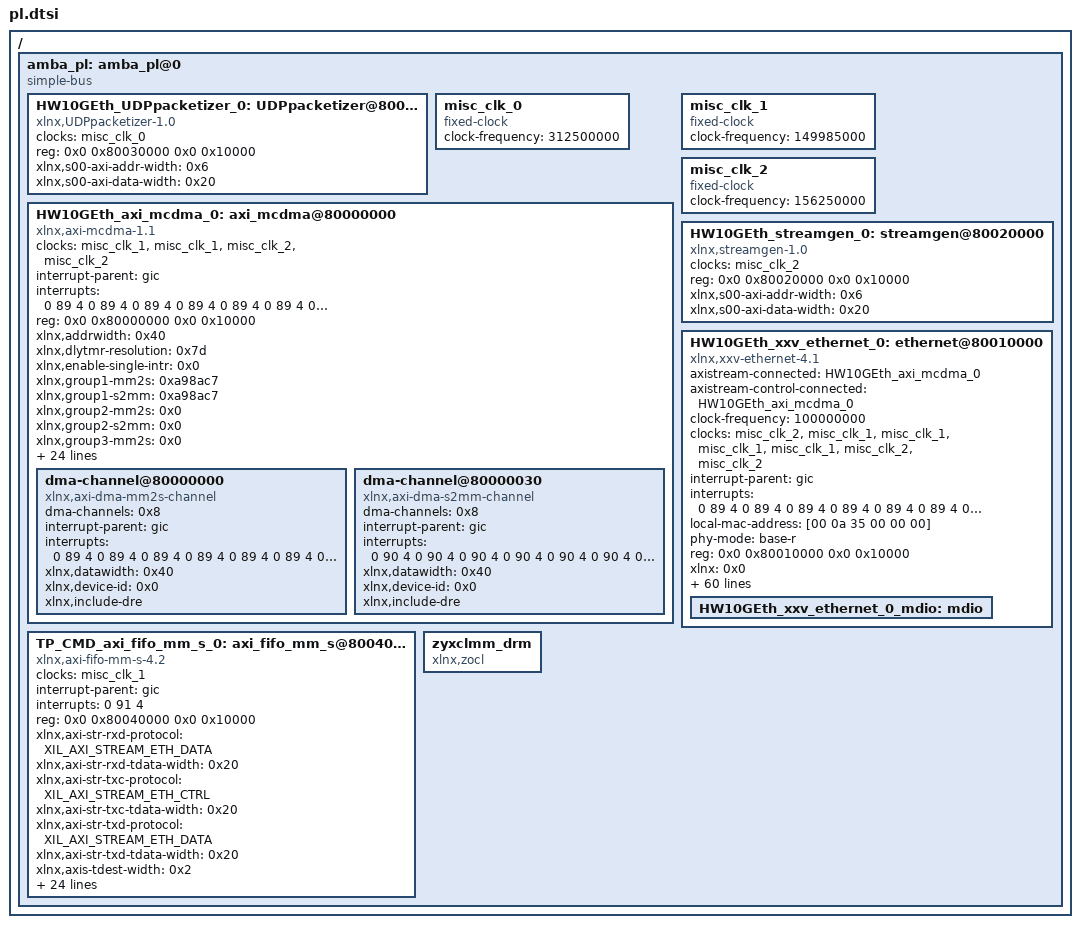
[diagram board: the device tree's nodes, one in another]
/*
 * CAUTION: This file is automatically generated by Xilinx.
 * Version: XSCT 
 * Today is: Mon Sep  4 14:09:04 2023
 */


/ {
	amba_pl: amba_pl@0 {
		#address-cells = <2>;
		#size-cells = <2>;
		compatible = "simple-bus";
		ranges ;
		HW10GEth_UDPpacketizer_0: UDPpacketizer@80030000 {
			clock-names = "aclk";
			clocks = <&misc_clk_0>;
			compatible = "xlnx,UDPpacketizer-1.0";
			reg = <0x0 0x80030000 0x0 0x10000>;
			xlnx,s00-axi-addr-width = <0x6>;
			xlnx,s00-axi-data-width = <0x20>;
		};
		misc_clk_0: misc_clk_0 {
			#clock-cells = <0>;
			clock-frequency = <312500000>;
			compatible = "fixed-clock";
		};
		HW10GEth_axi_mcdma_0: axi_mcdma@80000000 {
			#dma-cells = <1>;
			clock-names = "s_axi_lite_aclk", "m_axi_sg_aclk", "m_axi_mm2s_aclk", "m_axi_s2mm_aclk";
			clocks = <&misc_clk_1>, <&misc_clk_1>, <&misc_clk_2>, <&misc_clk_2>;
			compatible = "xlnx,axi-mcdma-1.1", "xlnx,axi-mcdma-1.00.a";
			interrupt-names = "mm2s_ch1_introut", "mm2s_ch2_introut", "mm2s_ch3_introut", "mm2s_ch4_introut", "mm2s_ch5_introut", "mm2s_ch6_introut", "mm2s_ch7_introut", "mm2s_ch8_introut", "s2mm_ch1_introut", "s2mm_ch2_introut", "s2mm_ch3_introut", "s2mm_ch4_introut", "s2mm_ch5_introut", "s2mm_ch6_introut", "s2mm_ch7_introut", "s2mm_ch8_introut";
			interrupt-parent = <&gic>;
			interrupts = <0 89 4 0 89 4 0 89 4 0 89 4 0 89 4 0 89 4 0 89 4 0 89 4 0 90 4 0 90 4 0 90 4 0 90 4 0 90 4 0 90 4 0 90 4 0 90 4>;
			reg = <0x0 0x80000000 0x0 0x10000>;
			xlnx,addrwidth = <0x40>;
			xlnx,dlytmr-resolution = <0x7d>;
			xlnx,enable-single-intr = <0x0>;
			xlnx,group1-mm2s = <0xa98ac7>;
			xlnx,group1-s2mm = <0xa98ac7>;
			xlnx,group2-mm2s = <0x0>;
			xlnx,group2-s2mm = <0x0>;
			xlnx,group3-mm2s = <0x0>;
			xlnx,group3-s2mm = <0x0>;
			xlnx,group4-mm2s = <0x0>;
			xlnx,group4-s2mm = <0x0>;
			xlnx,group5-mm2s = <0x0>;
			xlnx,group5-s2mm = <0x0>;
			xlnx,group6-mm2s = <0x0>;
			xlnx,group6-s2mm = <0x0>;
			xlnx,include-dre ;
			xlnx,include-mm2s = <0x1>;
			xlnx,include-mm2s-dre = <0x1>;
			xlnx,include-mm2s-sf = <0x1>;
			xlnx,include-s2mm = <0x1>;
			xlnx,include-s2mm-dre = <0x1>;
			xlnx,include-s2mm-sf = <0x1>;
			xlnx,include-sg ;
			xlnx,mm2s-burst-size = <0x100>;
			xlnx,mm2s-scheduler = <0x2>;
			xlnx,num-mm2s-channels = <0x8>;
			xlnx,num-s2mm-channels = <0x8>;
			xlnx,prmry-is-aclk-async = <0x1>;
			xlnx,s2mm-burst-size = <0x100>;
			xlnx,sg-include-stscntrl-strm = <0x0>;
			xlnx,sg-length-width = <0x17>;
			xlnx,sg-use-stsapp-length = <0x0>;
			dma-channel@80000000 {
				compatible = "xlnx,axi-dma-mm2s-channel";
				dma-channels = <0x8>;
				interrupt-parent = <&gic>;
				interrupts = <0 89 4 0 89 4 0 89 4 0 89 4 0 89 4 0 89 4 0 89 4 0 89 4>;
				xlnx,datawidth = <0x40>;
				xlnx,device-id = <0x0>;
				xlnx,include-dre ;
			};
			dma-channel@80000030 {
				compatible = "xlnx,axi-dma-s2mm-channel";
				dma-channels = <0x8>;
				interrupt-parent = <&gic>;
				interrupts = <0 90 4 0 90 4 0 90 4 0 90 4 0 90 4 0 90 4 0 90 4 0 90 4>;
				xlnx,datawidth = <0x40>;
				xlnx,device-id = <0x0>;
				xlnx,include-dre ;
			};
		};
		misc_clk_1: misc_clk_1 {
			#clock-cells = <0>;
			clock-frequency = <149985000>;
			compatible = "fixed-clock";
		};
		misc_clk_2: misc_clk_2 {
			#clock-cells = <0>;
			clock-frequency = <156250000>;
			compatible = "fixed-clock";
		};
		HW10GEth_streamgen_0: streamgen@80020000 {
			clock-names = "aclk";
			clocks = <&misc_clk_2>;
			compatible = "xlnx,streamgen-1.0";
			reg = <0x0 0x80020000 0x0 0x10000>;
			xlnx,s00-axi-addr-width = <0x6>;
			xlnx,s00-axi-data-width = <0x20>;
		};
		HW10GEth_xxv_ethernet_0: ethernet@80010000 {
			axistream-connected = <&HW10GEth_axi_mcdma_0>;
			axistream-control-connected = <&HW10GEth_axi_mcdma_0>;
			clock-frequency = <100000000>;
			clock-names = "rx_core_clk", "dclk", "s_axi_aclk", "s_axi_lite_aclk", "m_axi_sg_aclk", "m_axi_mm2s_aclk", "m_axi_s2mm_aclk";
			clocks = <&misc_clk_2>,  <&misc_clk_1>,  <&misc_clk_1>, <&misc_clk_1>, <&misc_clk_1>, <&misc_clk_2>, <&misc_clk_2>;
			compatible = "xlnx,xxv-ethernet-4.1", "xlnx,xxv-ethernet-1.0";
			device_type = "network";
			interrupt-names = "mm2s_ch1_introut", "mm2s_ch2_introut", "mm2s_ch3_introut", "mm2s_ch4_introut", "mm2s_ch5_introut", "mm2s_ch6_introut", "mm2s_ch7_introut", "mm2s_ch8_introut", "s2mm_ch1_introut", "s2mm_ch2_introut", "s2mm_ch3_introut", "s2mm_ch4_introut", "s2mm_ch5_introut", "s2mm_ch6_introut", "s2mm_ch7_introut", "s2mm_ch8_introut";
			interrupt-parent = <&gic>;
			interrupts = <0 89 4 0 89 4 0 89 4 0 89 4 0 89 4 0 89 4 0 89 4 0 89 4 0 90 4 0 90 4 0 90 4 0 90 4 0 90 4 0 90 4 0 90 4 0 90 4>;
			local-mac-address = [00 0a 35 00 00 00];
			phy-mode = "base-r";
			reg = <0x0 0x80010000 0x0 0x10000>;
			xlnx = <0x0>;
			xlnx,add-gt-cntrl-sts-ports = <0x0>;
			xlnx,anlt-clk-in-mhz = <0x64>;
			xlnx,axis-tdata-width = <0x40>;
			xlnx,axis-tkeep-width = <0x7>;
			xlnx,base-r-kr = "BASE-R";
			xlnx,channel-ids = "1","2","3","4","5","6","7","8";
			xlnx,clocking = "Asynchronous";
			xlnx,cmac-core-select = "CMACE4_X0Y0";
			xlnx,core = "Ethernet MAC+PCS/PMA 64-bit";
			xlnx,data-path-interface = "AXI Stream";
			xlnx,enable-datapath-parity = <0x0>;
			xlnx,enable-gt-board-interface = <0x1>;
			xlnx,enable-pipeline-reg = <0x0>;
			xlnx,enable-preemption = <0x0>;
			xlnx,enable-preemption-fifo = <0x0>;
			xlnx,enable-rx-flow-control-logic = <0x0>;
			xlnx,enable-time-stamping = <0x0>;
			xlnx,enable-tx-flow-control-logic = <0x0>;
			xlnx,enable-vlane-adjust-mode = <0x0>;
			xlnx,family-chk = "zynquplus";
			xlnx,fast-sim-mode = <0x0>;
			xlnx,gt-diffctrl-width = <0x4>;
			xlnx,gt-drp-clk = "100.00";
			xlnx,gt-group-select = "Quad X0Y0";
			xlnx,gt-location = <0x1>;
			xlnx,gt-ref-clk-freq = "156.25";
			xlnx,gt-type = "GTH";
			xlnx,gtm-group-select = "NA";
			xlnx,include-auto-neg-lt-logic = "None";
			xlnx,include-axi4-interface = <0x1>;
			xlnx,include-dre ;
			xlnx,include-fec-logic = <0x0>;
			xlnx,include-hybrid-cmac-rsfec-logic = <0x0>;
			xlnx,include-rsfec-logic = <0x0>;
			xlnx,include-shared-logic = <0x1>;
			xlnx,include-statistics-counters = <0x1>;
			xlnx,include-user-fifo = <0x1>;
			xlnx,ins-loss-nyq = <0x1e>;
			xlnx,lane1-gt-loc = "X1Y12";
			xlnx,lane2-gt-loc = "NA";
			xlnx,lane3-gt-loc = "NA";
			xlnx,lane4-gt-loc = "NA";
			xlnx,line-rate = <0xa>;
			xlnx,mii-ctrl-width = <0x4>;
			xlnx,mii-data-width = <0x20>;
			xlnx,num-of-cores = <0x1>;
			xlnx,num-queues = /bits/ 16 <0x8>;
			xlnx,ptp-clocking-mode = <0x0>;
			xlnx,ptp-operation-mode = <0x2>;
			xlnx,runtime-switch = <0x0>;
			xlnx,rx-eq-mode = "AUTO";
			xlnx,rxmem = <0x40000>;
			xlnx,statistics-regs-type = <0x0>;
			xlnx,switch-1-10-25g = <0x0>;
			xlnx,sys-clk = <0xfa0>;
			xlnx,tx-latency-adjust = <0x0>;
			xlnx,tx-total-bytes-width = <0x4>;
			xlnx,xgmii-interface = <0x1>;
			zclock-names = "NULL";
			zclocks = "NULL";
			HW10GEth_xxv_ethernet_0_mdio: mdio {
				#address-cells = <1>;
				#size-cells = <0>;
			};
		};
		TP_CMD_axi_fifo_mm_s_0: axi_fifo_mm_s@80040000 {
			clock-names = "s_axi_aclk";
			clocks = <&misc_clk_1>;
			compatible = "xlnx,axi-fifo-mm-s-4.2";
			interrupt-names = "interrupt";
			interrupt-parent = <&gic>;
			interrupts = <0 91 4>;
			reg = <0x0 0x80040000 0x0 0x10000>;
			xlnx,axi-str-rxd-protocol = "XIL_AXI_STREAM_ETH_DATA";
			xlnx,axi-str-rxd-tdata-width = <0x20>;
			xlnx,axi-str-txc-protocol = "XIL_AXI_STREAM_ETH_CTRL";
			xlnx,axi-str-txc-tdata-width = <0x20>;
			xlnx,axi-str-txd-protocol = "XIL_AXI_STREAM_ETH_DATA";
			xlnx,axi-str-txd-tdata-width = <0x20>;
			xlnx,axis-tdest-width = <0x2>;
			xlnx,axis-tid-width = <0x4>;
			xlnx,axis-tuser-width = <0x4>;
			xlnx,data-interface-type = <0x0>;
			xlnx,has-axis-tdest = <0x1>;
			xlnx,has-axis-tid = <0x0>;
			xlnx,has-axis-tkeep = <0x1>;
			xlnx,has-axis-tstrb = <0x0>;
			xlnx,has-axis-tuser = <0x0>;
			xlnx,rx-cascade-height = <0x0>;
			xlnx,rx-fifo-depth = <0x4000>;
			xlnx,rx-fifo-pe-threshold = <0x5>;
			xlnx,rx-fifo-pf-threshold = <0x3ffb>;
			xlnx,s-axi-id-width = <0x4>;
			xlnx,s-axi4-data-width = <0x20>;
			xlnx,select-xpm = <0x0>;
			xlnx,tx-cascade-height = <0x0>;
			xlnx,tx-fifo-depth = <0x4000>;
			xlnx,tx-fifo-pe-threshold = <0x5>;
			xlnx,tx-fifo-pf-threshold = <0x3ffb>;
			xlnx,use-rx-cut-through = <0x0>;
			xlnx,use-rx-data = <0x1>;
			xlnx,use-tx-ctrl = <0x0>;
			xlnx,use-tx-cut-through = <0x0>;
			xlnx,use-tx-data = <0x1>;
		};
		zyxclmm_drm {
			compatible = "xlnx,zocl";
		};
	};
};
